# ATmega16HVA register map
Vendor: Atmel; File version: 1.0
CPU: other r0p0, little endian, no MPU, no FPU, 4 interrupt priority bits
Registers are 8-bit, read-write, reset 0x0 unless marked. A register's access mark holds for its fields unless they carry their own. Offsets are from the block's base; [hi:lo] are bit positions; {n}, {i} and the like mark numbered series.

## BOOT_LOAD — Bootloader
Base 0x00800057
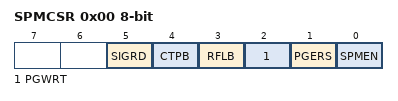
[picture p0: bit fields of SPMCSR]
0x00 SPMCSR — Store Program Memory Control and Status Register
  [5] SIGRD — Signature Row Read
  [4] CTPB — Clear Temporary Page Buffer
  [3] RFLB — Read Fuse and Lock Bits
  [2] PGWRT — Page Write
  [1] PGERS — Page Erase
  [0] SPMEN — Store Program Memory Enable

## COULOMB_COUNTER
Base 0x008000E0
{0x0+i} CADAC{i} (i=0..3) — ADC Accumulate Current (read-only for debugger)
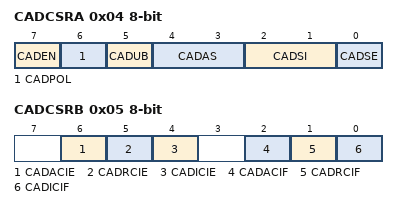
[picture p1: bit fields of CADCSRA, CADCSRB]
0x04 CADCSRA — CC-ADC Control and Status Register A
  [7] CADEN — When the CADEN bit is cleared (zero), the CC-ADC is disabled. When the CADEN bit is set (one), the CC-ADC will continuously measure the voltage drop over the external sense resistor RSENSE. In Power-down, only the Regular Current detection is active. In Power-off, the CC-ADC is always disabled.
  [6] CADPOL
  [5] CADUB — CC_ADC Update Busy
  [4:3] CADAS — CC_ADC Accumulate Current Select Bits
  [2:1] CADSI — The CADSI bits determine the current sampling interval for the Regular Current detection in Power-down mode. The actual settings remain to be determined.
  [0] CADSE — When the CADSE bit is written to one, the ongoing CC-ADC conversion is aborted, and the CC-ADC enters Regular Current detection mode.
0x05 CADCSRB — CC-ADC Control and Status Register B
  [6] CADACIE
  [5] CADRCIE — Regular Current Interrupt Enable
  [4] CADICIE — CAD Instantaneous Current Interrupt Enable
  [2] CADACIF — CC-ADC Accumulate Current Interrupt Flag
  [1] CADRCIF — CC-ADC Accumulate Current Interrupt Flag
  [0] CADICIF — CC-ADC Instantaneous Current Interrupt Flag
0x06 CADRC — CC-ADC Regular Current
0x08 CADIC 16-bit (reset mask 0xFF) — CC-ADC Instantaneous Current

## CPU — CPU Registers
Base 0x00800037
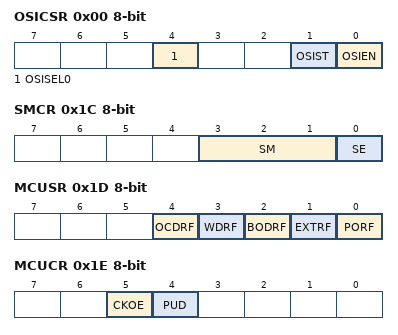
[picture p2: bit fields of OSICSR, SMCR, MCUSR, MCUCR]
0x00 OSICSR — Oscillator Sampling Interface Control and Status Register (read-only for debugger)
  [4] OSISEL0 — Oscillator Sampling Interface Select 0
  [1] OSIST — Oscillator Sampling Interface Status
  [0] OSIEN — Oscillator Sampling Interface Enable
0x07 GPIOR0 — General Purpose IO Register 0
0x13 GPIOR1 — General Purpose IO Register 1
0x14 GPIOR2 — General Purpose IO Register 2
0x1C SMCR — Sleep Mode Control Register
  [3:1] SM — Sleep Mode Select bits
    0=IDLE; 1=ADC (ADC Noise Reduction (If Available)); 3=PSAVE (Power Save); 4=POFF (Power Off)
  [0] SE — Sleep Enable
0x1D MCUSR — MCU Status Register (read-only for debugger)
  [4] OCDRF — OCD Reset Flag
  [3] WDRF — Watchdog Reset Flag
  [2] BODRF — Brown-out Reset Flag
  [1] EXTRF — External Reset Flag
  [0] PORF — Power-on reset flag
0x1E MCUCR — MCU Control Register
  [5] CKOE — Clock Output Enable
  [4] PUD — Pull-up disable
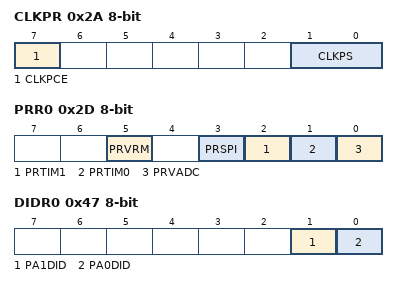
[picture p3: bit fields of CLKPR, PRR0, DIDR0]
0x2A CLKPR — Clock Prescale Register (read-only for debugger)
  [7] CLKPCE — Clock Prescaler Change Enable
  [1:0] CLKPS — Clock Prescaler Select Bits
0x2D PRR0 — Power Reduction Register 0
  [5] PRVRM — Power Reduction Voltage Regulator Monitor
  [3] PRSPI — Power reduction SPI
  [2] PRTIM1 — Power Reduction Timer/Counter1
  [1] PRTIM0 — Power Reduction Timer/Counter0
  [0] PRVADC — Power Reduction V-ADC
0x2F FOSCCAL — Fast Oscillator Calibration Value
0x47 DIDR0 — Digital Input Disable Register
  [1] PA1DID — When this bit is written logic one, the digital input buffer of the corresponding V_ADC pin is disabled.
  [0] PA0DID — When this bit is written logic one, the digital input buffer of the corresponding V_ADC pin is disabled.

## EEPROM
Base 0x0080003F
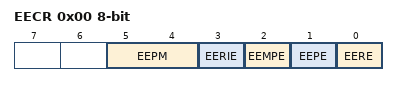
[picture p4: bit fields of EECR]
0x00 EECR — EEPROM Control Register
  [5:4] EEPM
    0=ERASE_AND_WRITE_IN_ONE_OPERATION; 1=ERASE_ONLY; 2=WRITE_ONLY
  [3] EERIE — EEProm Ready Interrupt Enable
  [2] EEMPE — EEPROM Master Write Enable
  [1] EEPE — EEPROM Write Enable
  [0] EERE — EEPROM Read Enable
0x01 EEDR — EEPROM Data Register
0x02 EEAR — EEPROM Read/Write Access
